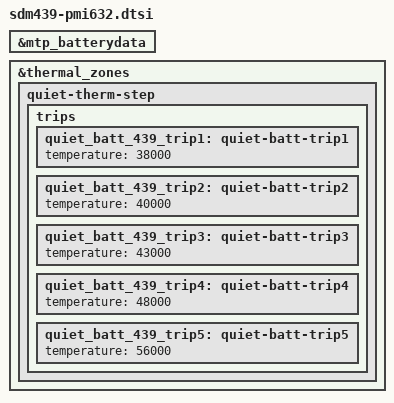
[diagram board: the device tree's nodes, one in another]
&mtp_batterydata {
	#include "batterydata/Peony-GY-4000mah-51kohm.dtsi"
	#include "batterydata/Peony-NVT-4000mah-41kohm.dtsi"
	#include "batterydata/Peony-SWD-4000mah-78kohm.dtsi"
	#include "batterydata/Peony-Default-4000mah-78kohm.dtsi"
};

&thermal_zones {
	quiet-therm-step {
		trips {
			quiet_batt_439_trip1: quiet-batt-trip1 {
				temperature = <38000>;
			};
			quiet_batt_439_trip2: quiet-batt-trip2 {
				temperature = <40000>;
			};
			quiet_batt_439_trip3: quiet-batt-trip3 {
				temperature = <43000>;
			};
			quiet_batt_439_trip4: quiet-batt-trip4 {
				temperature = <48000>;
			};
			quiet_batt_439_trip5: quiet-batt-trip5 {
				temperature = <56000>;
			};
		};
	};
};
